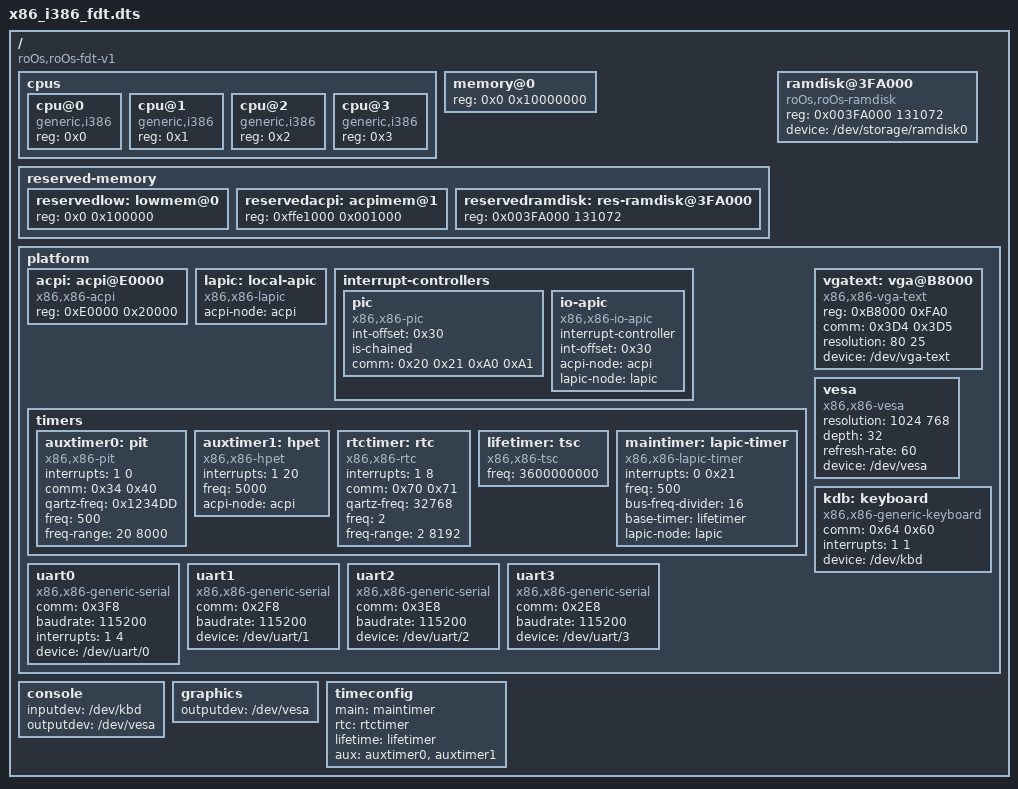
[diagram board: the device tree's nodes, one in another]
/dts-v1/;

/ {
    compatible = "roOs,roOs-fdt-v1";

    #address-cells = <1>;
    #size-cells = <1>;

    cpus {
        #address-cells = <1>;
        #size-cells = <0>;
        cpu@0 {
            compatible = "generic,i386";
            reg = <0x0>;
        };
        cpu@1 {
            compatible = "generic,i386";
            reg = <0x1>;
        };
        cpu@2 {
            compatible = "generic,i386";
            reg = <0x2>;
        };
        cpu@3 {
            compatible = "generic,i386";
            reg = <0x3>;
        };
    };

    memory@0 {
        #address-cells = <1>;
        #size-cells = <1>;

        device_type = "memory";
        reg = <0x0 0x10000000>;
    };

    reserved-memory {
        #address-cells = <1>;
        #size-cells = <1>;
        ranges;
        reservedlow: lowmem@0 {
            reg = <0x0 0x100000>;
        };
        reservedacpi: acpimem@1 {
            reg = <0xffe1000 0x001000>;
        };
        reservedramdisk: res-ramdisk@3FA000 {
            reg = <0x003FA000 131072>;
        };
    };

    ramdisk@3FA000 {
        compatible = "roOs,roOs-ramdisk";
        reg = <0x003FA000 131072>;
        device = "/dev/storage/ramdisk0";
    };

    platform {
        #address-cells = <1>;
        #size-cells = <1>;

        acpi: acpi@E0000 {
            compatible = "x86,x86-acpi";
            reg = <0xE0000 0x20000>;
        };

        lapic: local-apic {
            compatible = "x86,x86-lapic";
            acpi-node = <&acpi>;
        };

        /* Interrupt controller must be placed before any device using
         * interrupts.
         *
         * Only one controller be set as interrupt-controller, the rest should
         * must be disabled by commenting or removinf the attribute.
         * It is important to keep all node to ensure the hardware is corrtly
         * initialized. The node can be removed if the component is just not
         * present.
         */
        interrupt-controllers {
            pic {
                compatible = "x86,x86-pic";
                //interrupt-controller;
                #address-cells = <0>;
                #interrupt-cells = <2>;
                int-offset = <0x30>;
                is-chained;
                comm = <0x20 0x21 0xA0 0xA1>;
            };

            io-apic {
                compatible = "x86,x86-io-apic";
                interrupt-controller;
                #address-cells = <0>;
                #interrupt-cells = <2>;
                int-offset = <0x30>;
                acpi-node = <&acpi>;
                lapic-node = <&lapic>;
            };
        };

        /* PIT capabilities (global, synchronized, interrupt):
         *    * main
         *    * aux
         *
         * RTC capabilities (global, synchronized, interrupt):
         *    * rtc
         *    * aux
         *
         * TSC capabilities (per CPU, unsinchronized, no interrupt):
         *    * lifetime
         *    * aux
         *
         * HPET capabilities (global, synchronized, interrupt):
         *    * main
         *    * lifetime
         *    * aux
         *
         * LAPIC-Timer capabilities (per CPU, unsynchronized, interrupt):
         *    * main
         *    * aux
         *    * Note: the LAPIC timer needs a base timer to calibrate its
         *            frequency. The base timerneeds to support returning the
         *            current time in nanoseconds and must be as precise as
         *            possible.
         *
         * Set PIT as main for compatibility, low precision but synchronized
         * schedule and system ticks
         * Set HPET to main for global schedule and system ticks
         * synchronization over all CPUS.
         * Set LAPIC-Timers as main for more precise but unsynchronized
         * schedule and system ticks
         */
        timers {
            auxtimer0: pit {
                compatible = "x86,x86-pit";
                interrupts = <1 0>; /* 0: is IRQ; 1: IRQ line */
                comm = <0x34 0x40>;
                qartz-freq = <0x1234DD>;
                freq = <500>;
                freq-range = <20 8000>;
            };

            auxtimer1: hpet {
                compatible = "x86,x86-hpet";
                interrupts = <1 20>; /* 0: is IRQ; 1: IRQ line */
                freq = <5000>;
                acpi-node = <&acpi>;
            };

            rtctimer: rtc {
                compatible = "x86,x86-rtc";
                interrupts = <1 8>; /* 0: is IRQ; 1: IRQ line */
                comm = <0x70 0x71>;
                qartz-freq = <32768>;
                freq = <2>;
                freq-range = <2 8192>;
            };

            lifetimer: tsc {
                compatible = "x86,x86-tsc";
                freq = <3600000000>;
            };

            maintimer: lapic-timer {
                compatible = "x86,x86-lapic-timer";
                interrupts = <0 0x21>; /* 0: is not IRQ; 1: Int line */
                freq = <500>;
                bus-freq-divider = <16>;
                /* The current hardware has a fixed-rate TSC that is the most
                 * precise way to measure time.
                 */
                base-timer = <&lifetimer>;
                lapic-node = <&lapic>;
            };
        };

        vgatext: vga@B8000 {
            compatible = "x86,x86-vga-text";
            reg = <0xB8000 0xFA0>;
            comm = <0x3D4 0x3D5>;
            resolution = <80 25>;
            device = "/dev/vga-text";
        };

        vesa: vesa {
            compatible = "x86,x86-vesa";
            resolution = <1024 768>;
            depth = <32>;
            refresh-rate = <60>;
            device = "/dev/vesa";
        };

        kdb: keyboard {
            compatible = "x86,x86-generic-keyboard";
            comm = <0x64 0x60>;
            interrupts = <1 1>; /* 0: is IRQ; 1: IRQ line */
            device = "/dev/kbd";
        };

        uart0 {
            compatible = "x86,x86-generic-serial";
            comm = <0x3F8>;
            baudrate = <115200>;
            interrupts = <1 4>; /* 0: is IRQ; 1: IRQ line */
            device = "/dev/uart/0";
        };

        uart1 {
            compatible = "x86,x86-generic-serial";
            comm = <0x2F8>;
            baudrate = <115200>;
            device = "/dev/uart/1";
        };

        uart2 {
            compatible = "x86,x86-generic-serial";
            comm = <0x3E8>;
            baudrate = <115200>;
            device = "/dev/uart/2";
        };

        uart3 {
            compatible = "x86,x86-generic-serial";
            comm = <0x2E8>;
            baudrate = <115200>;
            device = "/dev/uart/3";
        };
    };

    console {
        inputdev = "/dev/kbd";
        outputdev = "/dev/vesa";
    };

    graphics {
        outputdev = "/dev/vesa";
    };

    timeconfig {
        main = <&maintimer>;
        rtc = <&rtctimer>;
        lifetime = <&lifetimer>;
        aux = <&auxtimer0 &auxtimer1>;
    };
};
